# EnumeratedValuesUsageTest register map
File version: 1.0
Minimal test for enumeratedValues usage field (read/write split enumerations)
Registers are 32-bit, read-write, no defined reset value unless marked. A register's access mark holds for its fields unless they carry their own. Offsets are from the block's base; lines under a group give offsets from that group; [hi:lo] are bit positions; {n}, {i} and the like mark numbered series; 'fields as' and 'values as' point back to an identical list; <NAME> marks a mode.

## Memory map
0x40000000 PERIPH0 size 0x100 — Test peripheral

## PERIPH0 — Test peripheral
Base 0x40000000
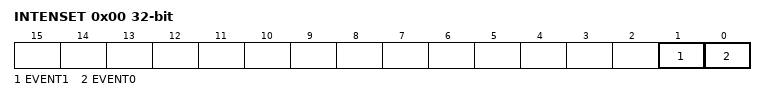
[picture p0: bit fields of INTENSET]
0x00 INTENSET — Enable interrupt (write 1 to set, read returns current state)
  [1] EVENT1 — Write '1' to enable interrupt for EVENT1
    on read: 0=Disabled (Interrupt is disabled); 1=Enabled (Interrupt is enabled) | on write: 1=Set (Enable the interrupt)
  [0] EVENT0 — Write '1' to enable interrupt for EVENT0
    values as EVENT1
